# M051DN_v1 register map
File version: 1.0
Registers are 32-bit, read-write, reset 0x0 unless marked. A register's access mark holds for its fields unless they carry their own. Offsets are from the block's base; [hi:lo] are bit positions; {n}, {i} and the like mark numbered series; 'fields as' and 'values as' point back to an identical list.

## CLK — CLK Register Map
Base 0x50000200
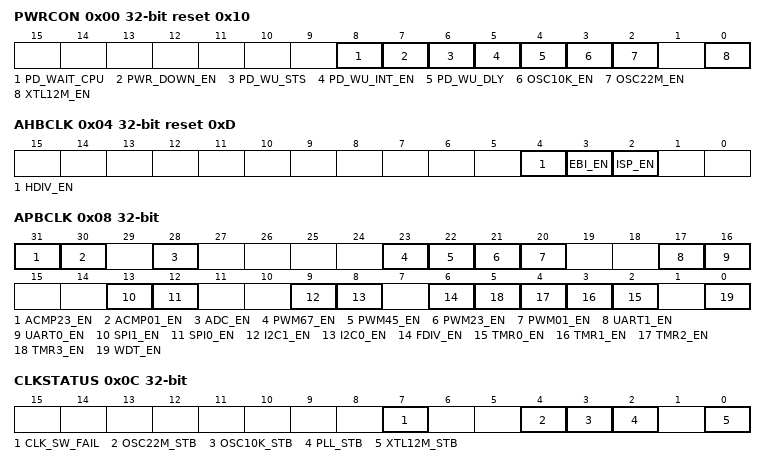
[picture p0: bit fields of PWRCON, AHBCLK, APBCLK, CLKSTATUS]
0x00 PWRCON reset 0x10 (reset mask 0xFFFFFFF0) — System Power-down Control Register
  [8] PD_WAIT_CPU — Power-down Entry Condition Control (Write Protect)
    0=Chip enters Power-down mode when the PWR_DOWN_EN bit is set to 1; 1=Chip enters Power- down mode when the both PD_WAIT_CPU and PWR_DOWN_EN bits are set to 1 and CPU run WFI instruction
  [7] PWR_DOWN_EN — System Power-down Enable Bit (Write Protect). When this bit is set to 1, Power-down mode is enabled and chip Power-down behavior will depend on the PD_WAIT_CPU bit (a) If the PD_WAIT_CPU is 0, then the chip enters Power-down mode immediately after the PWR_DOWN_EN bit set. (b) If the PD_WAIT_CPU is 1, then the chip keeps active till CPU run WFI instruction. When chip wakes up from Power-down mode, this bit is cleared by hardware. User needs to set this bit again for next Power-down. In Power-down mode, 4~24 MHz external high speed crystal oscillator (HXT) and the 22.1184 MHz internal high speed oscillator (HIRC) will be disabled in this mode, and 10 kHz internal low speed RC oscillator (LIRC) are not controlled by Power-down mode. In Power- down mode, the PLL and system clock are disabled, and ignored the clock source selection. The clocks of peripheral are not controlled by Power-down mode, if the peripheral clock source is from 10 kHz internal low speed oscillator.
    0=Chip operating normally or chip in Idle mode because of WFI command; 1=Chip enters Power-down mode instantly or waits CPU sleep command WFI
  [6] PD_WU_STS — Power-down Mode Wake-up Interrupt Status. Set by "Power-down wake-up event", which indicates that resume from Power-down mode" The flag is set if the GPIO, UART, WDT, ACMP or BOD wake-up occurred. Note: This bit works only if PD_WU_INT_EN (PWRCON[5]) set to 1. Write 1 to clear the bit to 0.
  [5] PD_WU_INT_EN — Power-down Mode Wake-up Interrupt Enable Control (Write Protect). Note: The interrupt will occur when both PD_WU_STS and PD_WU_INT_EN are high.
    0=Disabled; 1=Enabled
  [4] PD_WU_DLY — Wake-up Delay Counter Enable Control (Write Protect). When the chip wakes up from Power-down mode, the clock control will delay certain clock cycles to wait system clock stable. The delayed clock cycle is 4096 clock cycles when chip works at 4~24 MHz external high speed crystal (HXT), and 256 clock cycles when chip works at 22.1184 MHz internal high speed RC oscillator (HIRC).
    0=Clock cycles delay Disabled; 1=Clock cycles delay Enabled
  [3] OSC10K_EN — 10 KHz Internal Low Speed RC Oscillator (LIRC) Enable Control (Write Protect)
    0=10 kHz internal low speed RC oscillator (LIRC) Disabled; 1=10 kHz internal low speed RC oscillator (LIRC) Enabled
  [2] OSC22M_EN — 22.1184 MHz Internal High Speed RC Oscillator (HIRC) Enable Control (Write Protect)
    0=22.1184 MHz internal high speed RC oscillator (HIRC) Disabled; 1=22.1184 MHz internal high speed RC oscillator (HIRC) Enabled
  [0] XTL12M_EN — 4~24 MHz External High Speed Crystal (HXT) Enable Control (Write Protect). The bit default value is set by flash controller user configuration register config0 [26:24]. When the default clock source is from 4~24 MHz external high speed crystal, this bit is set to 1 automatically.
    0=4 ~ 24 MHz external high speed crystal oscillator (HXT) Disabled; 1=4 ~ 24 MHz external high speed crystal oscillator (HXT) Enabled
0x04 AHBCLK reset 0xD — AHB Devices Clock Enable Control Register
  [4] HDIV_EN — Divider Controller Clock Enable Control (M05xxDN/DE Only)
    0=Divider controller peripheral clock Disabled; 1=Divider controller peripheral clock Enabled
  [3] EBI_EN — EBI Controller Clock Enable Control
    0=EBI peripheral clock Disabled; 1=EBI peripheral clock Enabled
  [2] ISP_EN — Flash ISP Controller Clock Enable Control
    0=Flash ISP peripheral clock Disabled; 1=Flash ISP peripheral clock Enabled
0x08 APBCLK (reset mask 0xFFFFFFF0) — APB Devices Clock Enable Control Register
  [31] ACMP23_EN — Analog Comparator 2/3 Clock Enable Control (M051xxDN/DE Only)
    0=Analog Comparator 2/3 clock Disabled; 1=Analog Comparator 2/3 clock Enabled
  [30] ACMP01_EN — Analog Comparator 0/1 Clock Enable Control
    0=Analog Comparator 0/1 clock Disabled; 1=Analog Comparator 0/1 clock Enabled
  [28] ADC_EN — Analog-digital-converter (ADC) Clock Enable Control
    0=ADC peripheral clock Disabled; 1=ADC peripheral clock Enabled
  [23] PWM67_EN — PWM_67 Clock Enable Control
    0=PWM67 clock Disabled; 1=PWM67 clock Enabled
  [22] PWM45_EN — PWM_45 Clock Enable Control
    0=PWM45 clock Disabled; 1=PWM45 clock Enabled
  [21] PWM23_EN — PWM_23 Clock Enable Control
    0=PWM23 clock Disabled; 1=PWM23 clock Enabled
  [20] PWM01_EN — PWM_01 Clock Enable Control
    0=PWM01 clock Disabled; 1=PWM01 clock Enabled
  [17] UART1_EN — UART1 Clock Enable Control
    0=UART1 clock Disabled; 1=UART1 clock Enabled
  [16] UART0_EN — UART0 Clock Enable Control
    0=UART0 clock Disabled; 1=UART0 clock Enabled
  [13] SPI1_EN — SPI1 Peripheral Clock Enable Control
    0=SPI1 peripheral clock Disabled; 1=SPI1 peripheral clock Enabled
  [12] SPI0_EN — SPI0 Peripheral Clock Enable Control
    0=SPI0 peripheral clock Disabled; 1=SPI0 peripheral clock Enabled
  [9] I2C1_EN — I2C1 Clock Enable Control (M051xxDN/DE Only)
    0=I2C clock Disabled; 1=I2C clock Enabled
  [8] I2C0_EN — I2C0 Clock Enable Control
    0=I2C clock Disabled; 1=I2C clock Enabled
  [6] FDIV_EN — Frequency Divider Output Clock Enable Control
    0=FDIV clock Disabled; 1=FDIV clock Enabled
  [n+2] TMR{n}_EN (n=0..3) — Timer{n} Clock Enable Control
    0=Timer{n} clock Disabled; 1=Timer{n} clock Enabled
  [0] WDT_EN — Watchdog Timer Clock Enable Control (Write Protect). Note: This bit is the protected bit, and programming it needs to write "59h", "16h", and "88h" to address 0x5000_0100 to disable register protection. Refer to the register REGWRPROT at address GCR_BA+0x100.
    0=Watchdog Timer clock Disabled; 1=Watchdog Timer clock Enabled
0x0C CLKSTATUS (reset mask 0xFFFFFF00) — Clock Status Monitor Register
  [7] CLK_SW_FAIL — Clock Switching Fail Flag. Note1: This bit is updated when software switches system clock source. If switch target clock is stable, this bit will be set to 0. If switch target clock is not stable, this bit will be set to 1. Note2: On M05xxBN, software can write 1 to clear the bit to 0. Note3: On M05xxDN/DE, this bit is read only. After selected clock source is stable, hardware will switch system clock to selected clock automatically, and CLK_SE_FAIL will be cleared automatically by hardware.
    0=Clock switching success; 1=Clock switching failed
  [4] OSC22M_STB ro — 22.1184 MHz Internal High Speed RC Oscillator (HIRC) Stable Flag (Read Only)
    0=22.1184 MHz internal high speed RC oscillator (HIRC) clock is not stable or disabled; 1=22.1184 MHz internal high speed RC oscillator (HIRC) clock is stable
  [3] OSC10K_STB ro — 10 KHz Internal Low Speed RC Oscillator (LIRC) Stable Flag (Read Only)
    0=10 kHz internal low speed RC oscillator (LIRC) clock is not stable or disabled; 1=10 kHz internal low speed RC oscillator (LIRC) clock is stable
  [2] PLL_STB ro — Internal PLL Clock Source Stable Flag (Read Only)
    0=Internal PLL clock is not stable or disabled; 1=Internal PLL clock is stable
  [0] XTL12M_STB ro — 4~24 MHz External High Speed Crystal (HXT) Stable Flag (Read Only)
    0=4~24 MHz external high speed crystal (HXT) clock is not stable or disabled; 1=4~24 MHz external high speed crystal (HXT) clock is stable
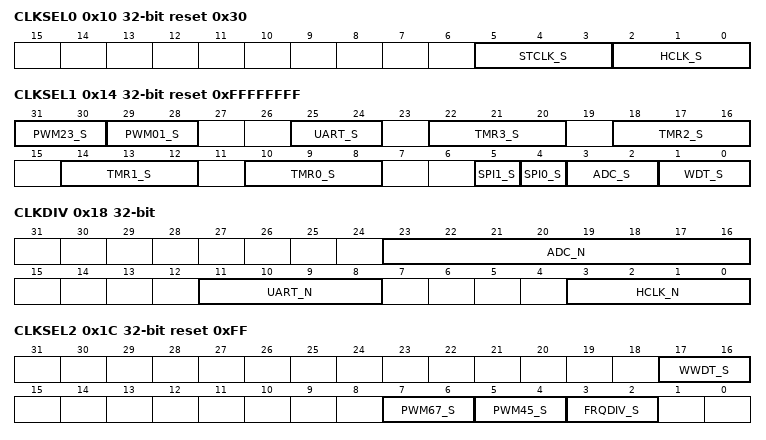
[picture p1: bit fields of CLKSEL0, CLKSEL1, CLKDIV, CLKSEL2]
0x10 CLKSEL0 reset 0x30 (reset mask 0xFFFFFFF0) — Clock Source Select Control Register 0
  [5:3] STCLK_S — Cortex-M0 SysTick Clock Source Selection From Reference Clock (Write Protect)
    0=Clock source is from HXT; 2=Clock source is from HXT/2; 3=Clock source is from HCLK/2; 7=Clock source is from HIRC/2
  [2:0] HCLK_S — HCLK Clock Source Selection (Write Protect). Note1: Before clock switching, the related clock sources (both pre-select and new-select) must be turn-on and stable. Note2: The 3-bit default value is reloaded from the value of CFOSC (CONFIG0[26:24]) in user configuration register of Flash controller by any reset. Therefore the default value is either 000b or 111b. Note3: These bits are protected bit, and programming them needs to write "59h", "16h", and "88h" to address 0x5000_0100 to disable register protection. Refer to the register REGWRPROT at address GCR_BA+0x100.
    0=Clock source is from HXT; 2=Clock source is from PLL; 3=Clock source is from LIRC; 7=Clock source is from HIRC
0x14 CLKSEL1 reset 0xFFFFFFFF — Clock Source Select Control Register 1
  [31:30] PWM23_S — PWM2 and PWM3 Clock Source Selection. PWM2 and PWM3 use the same peripheral clock source; both of them use the same prescaler.
    0=Clock source is from HXT; 1=Clock source is from LIRC. (M051xxDN/DE Only); 2=Clock source is from HCLK; 3=Clock source is from HIRC
  [29:28] PWM01_S — PWM0 and PWM1 Clock Source Selection. PWM0 and PWM1 use the same peripheral clock source; both of them use the same prescaler.
    values as PWM23_S
  [25:24] UART_S — UART Clock Source Selection
    0=Clock source is from HXT; 1=Clock source is from PLL; 3=Clock source is from HIRC
  [4n+10:4n+8] TMR{n}_S (n=0..3) — TIMER{n} Clock Source Selection
    0=Clock source is from HXT; 2=Clock source is from HCLK; 3=Clock source is from external trigger T{n}. (M051xxDN/DE Only); 5=Clock source is from LIRC. (M051xxDN/DE Only); 7=Clock source is from HIRC
  [5] SPI1_S — SPI1 Clock Source Selection (M051xxDN/DE Only)
    0=Clock source is from PLL; 1=Clock source is from HCLK
  [4] SPI0_S — SPI0 Clock Source Selection (M051xxDN/DE Only)
    0=Clock source is from PLL; 1=Clock source is from HCLK
  [3:2] ADC_S — ADC Peripheral Clock Source Selection
    0=Clock source is from HXT; 1=Clock source is from PLL; 2=Clock source is from HCLK; 3=Clock source is from HIRC
  [1:0] WDT_S — Watchdog Timer Clock Source Selection (Write Protect). Note: These bits are protected bits, and programming them needs to write "59h", "16h", and "88h" to address 0x5000_0100 to disable register protection. Refer to the register REGWRPROT at address GCR_BA+0x100.
    2=Clock source is from HCLK/2048 clock; 3=Clock source is from LIRC
0x18 CLKDIV — Clock Divider Number Register
  [23:16] ADC_N — ADC Peripheral Clock Divide Number From ADC Peripheral Clock Source
  [11:8] UART_N — UART Clock Divide Number From UART Clock Source
  [3:0] HCLK_N — HCLK Clock Divide Number From HCLK Clock Source
0x1C CLKSEL2 reset 0xFF — Clock Source Select Control Register 2
  [17:16] WWDT_S — Window Watchdog Timer Clock Source Selection (M051xxDN/DE Only)
    values as CLKSEL1.WDT_S
  [7:6] PWM67_S — PWM6 and PWM7 Clock Source Selection. PWM6 and PWM7 used the same peripheral clock source; both of them used the same prescaler.
    values as CLKSEL1.PWM23_S
  [5:4] PWM45_S — PWM4 and PWM5 Clock Source Selection. PWM4 and PWM5 use the same peripheral clock source; both of them used the same prescaler.
    values as CLKSEL1.PWM23_S
  [3:2] FRQDIV_S — Clock Divider Clock Source Selection
    0=Clock source is from HXT; 1=Clock source is from LIRC. (M051xxDE Only); 2=Clock source is from HCLK; 3=Clock source is from HIRC
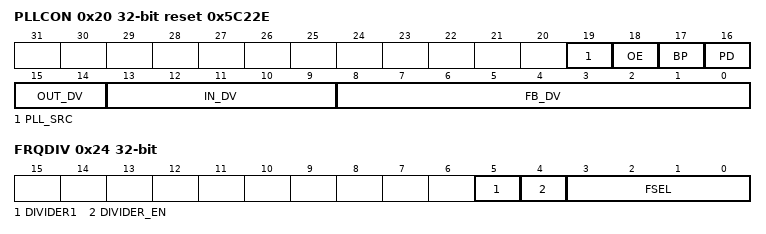
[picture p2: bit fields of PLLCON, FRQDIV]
0x20 PLLCON reset 0x5C22E — PLL Control Register
  [19] PLL_SRC — PLL Source Clock Selection
    0=PLL source clock from HXT; 1=PLL source clock from HIRC
  [18] OE — PLL OE (FOUT Enable) Pin Control
    0=PLL FOUT Enabled; 1=PLL FOUT is fixed low
  [17] BP — PLL Bypass Control
    0=PLL is in Normal mode (default); 1=PLL clock output is same as PLL source clock input
  [16] PD — Power-down Mode. If the PWR_DOWN_EN bit is set to 1 in PWRCON register, the PLL will enter Power-down mode too.
    0=PLL is in Normal mode; 1=PLL is in Power-down mode (default)
  [15:14] OUT_DV — PLL Output Divider Control. Refer to the formulas below the table.
  [13:9] IN_DV — PLL Input Divider Control. Refer to the formulas below the table.
  [8:0] FB_DV — PLL Feedback Divider Control. Refer to the formulas below the table.
0x24 FRQDIV — Frequency Divider Control Register
  [5] DIVIDER1 — Frequency Divider 1 Enable Control (M051xxDE Only)
    0=Divider output frequency is depended on FSEL value; 1=Divider output frequency is the same as input clock frequency
  [4] DIVIDER_EN — Frequency Divider Enable Control
    0=Frequency Divider Disabled; 1=Frequency Divider Enabled
  [3:0] FSEL — Divider Output Frequency Selection. The formula of output frequency is: Fin is the input clock frequency. Fout is the frequency of divider output clock. N is the 4-bit value of FSEL[3:0].
